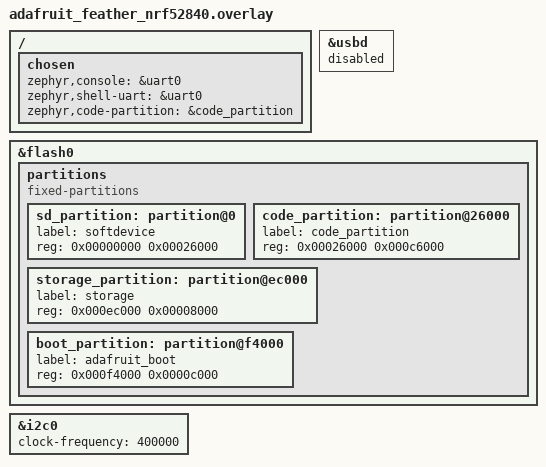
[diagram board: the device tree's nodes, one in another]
/* Joypad bt2usb — Adafruit Feather nRF52840 Express devicetree overlay
 *
 * TinyUSB drives USB hardware directly, so disable Zephyr's USBD node.
 * Console redirected to UART0 (TX=P0.25/D1, RX=P0.24/D0, 115200 baud).
 *
 * Override default MCUboot partitions with UF2-compatible layout
 * for the Adafruit nRF52 Bootloader (SoftDevice s140 v6).
 */

&usbd {
	status = "disabled";
};

/ {
	chosen {
		zephyr,console = &uart0;
		zephyr,shell-uart = &uart0;
	};
};

/* Remove default MCUboot partition layout */
/delete-node/ &boot_partition;
/delete-node/ &slot0_partition;
/delete-node/ &slot1_partition;
/delete-node/ &storage_partition;

&flash0 {
	/*
	 * UF2 flash layout for Adafruit Feather nRF52840 Express
	 *
	 * 0x00000000 SoftDevice s140 v6    (152 kB)
	 * 0x00026000 Application partition (792 kB)
	 * 0x000EC000 Storage partition     (32 kB)
	 * 0x000F4000 UF2 boot partition    (48 kB)
	 *
	 * See https://learn.adafruit.com/introducing-the-adafruit-nrf52840-feather/hathach-memory-map
	 */

	partitions {
		compatible = "fixed-partitions";
		#address-cells = <1>;
		#size-cells = <1>;

		sd_partition: partition@0 {
			label = "softdevice";
			reg = <0x00000000 0x00026000>;
		};

		code_partition: partition@26000 {
			label = "code_partition";
			reg = <0x00026000 0x000c6000>;
		};

		storage_partition: partition@ec000 {
			label = "storage";
			reg = <0x000ec000 0x00008000>;
		};

		boot_partition: partition@f4000 {
			label = "adafruit_boot";
			reg = <0x000f4000 0x0000c000>;
		};
	};
};

/ {
	chosen {
		zephyr,code-partition = &code_partition;
	};
};

/* FeatherWing OLED uses i2c0 — set 400kHz for fast display refresh */
&i2c0 {
	clock-frequency = <400000>;
};
